# Template register map
Vendor: VendorName Co.Ltd; Series: SeriesName; File version: 1.2
CPU: CM7 r0p1, little endian, MPU, FPU, 4 interrupt priority bits
Registers are 32-bit, read-write, no defined reset value unless marked. A register's access mark holds for its fields unless they carry their own. Offsets are from the block's base; [hi:lo] are bit positions; {n}, {i} and the like mark numbered series.

## MMATH — Math Operation Accelerator
Base 0x400BE000
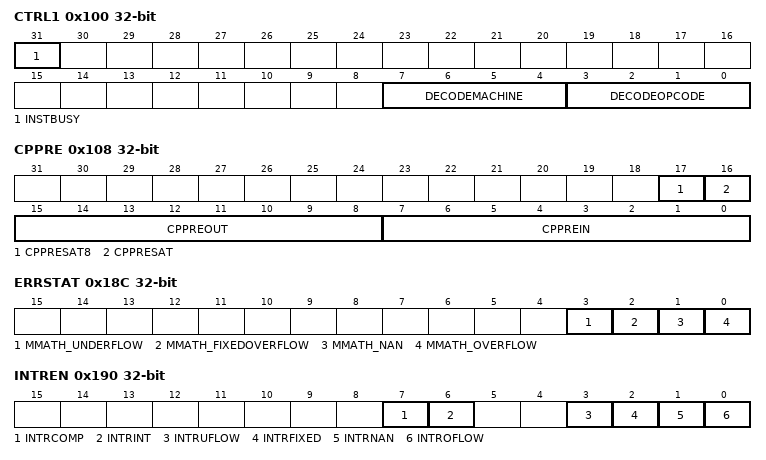
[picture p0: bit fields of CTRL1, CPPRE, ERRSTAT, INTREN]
0x100 CTRL1 — MMATH control register1
  [31] INSTBUSY ro — MMATH INSTBUSY bit: processing when instruct busy
  [7:4] DECODEMACHINE — MMATH DECODEMACHINE[3:0] bit: select corrsponding computational code
  [3:0] DECODEOPCODE — MMATH DECODEOPCODE[3:0] bit: specific opcode for decoder
0x108 CPPRE — MMATH pre-allocated register
  [17] CPPRESAT8 — MMATH CPPRESAT8 bit: co-processor saturation with 8 bits
  [16] CPPRESAT — MMATH CPPRESAT bit: co-processor saturation
  [15:8] CPPREOUT — MMATH CPPREOUT[7:0] bit: co-processor fixed point output
  [7:0] CPPREIN — MMATH CPPREIN[7:0] bit: co-processor scaling of input
0x110 CURSORY — MMATH cursory mode register
  [0] CURSORY — MMATH CURSORY bit: cursory mode enable selection
0x180 CORDICX — MMATH CORDIC input x register
  [31:0] CORDICX — MMATH CORDICX[31:0] bit: CORDIC input x
0x184 CORDICY — MMATH CORDIC input y register
  [31:0] CORDICY — MMATH CORDICY[31:0] bit: CORDIC input y
0x188 CORDICZ — MMATH CORDIC input z register
  [31:0] CORDICZ — MMATH CORDICZ[31:0] bit: CORDIC input z
0x18C ERRSTAT — MMATH error status register
  [3] MMATH_UNDERFLOW — MMATH MMATH_UNDERFLOW bit: underflow flag
  [2] MMATH_FIXEDOVERFLOW — MMATH MMATH_FIXEDOVERFLOW bit: fixed-point number overflow flag
  [1] MMATH_NAN — MMATH MMATH_NAN bit: NAN flag
  [0] MMATH_OVERFLOW — MMATH MMATH_OVERFLOW bit: overflow flag
0x190 INTREN — MMATH interrupt enable register
  [7] INTRCOMP — MMATH INTRCOMP bit: enable interruption request on instruction completion
  [6] INTRINT — MMATH INTRINT bit: global interruption flag enable
  [3] INTRUFLOW — MMATH INTRUFLOW bit: enable interruption request on underflow generation
  [2] INTRFIXED — MMATH INTRFIXED bit: enable interruption request on fixed-pointer number overflow generation
  [1] INTRNAN — MMATH INTRNAN bit: enable interruption request on NAN error generation
  [0] INTROFLOW — MMATH INTROFLOW bit: enable interruption request on overflow generation
0x198 INTRSTAT — MMATH interrupt status register
  [0] INTRSTAT — MMATH INTRSTAT bit: interrupt status register
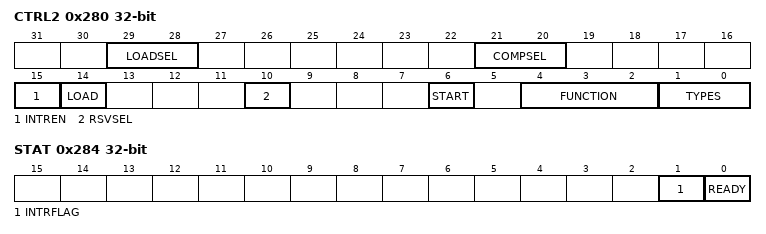
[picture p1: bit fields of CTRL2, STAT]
0x280 CTRL2 — MMATH control register2
  [29:28] LOADSEL — MMATH LOADSEL[1:0] bit: output type and calc unit select
  [21:20] COMPSEL — MMATH COMPSEL[1:0] bit: input type and clac unit select
  [15] INTREN — MMATH INTREN bit: calc finish interrupt enable
  [14] LOAD — MMATH LOAD bit: write 1 load result to read register
  [10] RSVSEL — MMATH RSVSEL bit: result select
  [6] START — MMATH START bit: start calc
  [4:2] FUNCTION — MMATH FUNCTION[2:0] bit: function select from calc types
  [1:0] TYPES — MMATH TYPES[1:0] bit: calc types
0x284 STAT — MMATH status register
  [1] INTRFLAG — MMATH INTRFLAG bit: operation completed interruption status flag bit
  [0] READY ro — MMATH READY bit: READY signal
0x290 WDATA0 — MMATH write data register 0
  [31:0] WDATA — MMATH WDATA[31:0] bit: low 32-bit data written
0x294 WDATA1 — MMATH write data register 1
  [31:0] WDATA — MMATH WDATA[31:0] bit: high 32-bit data written
0x298 RDATA0 ro — MMATH read data register 0
  [31:0] RDATA — MMATH RDATA[31:0] bit: low 32-bit data read
0x29C RDATA1 ro — MMATH read data register 1
  [31:0] RDATA — MMATH RDATA[31:0] bit: high 32-bit data read

## MU — Messaging Unit
Base 0x400C0000
{0x0+4i} TR{i} (i=0..3) — MU transmit register {i}
  [31:0] DATA — MU DATA[31:0] bit: use MUA transmit register {i} to transmit data to MUB
{0x10+4i} RR{i} ro (i=0..3) — MU receive register {i}
  [31:0] DATA — MU DATA[31:0] bit: use MUA receive register {i} to receive data from MUB
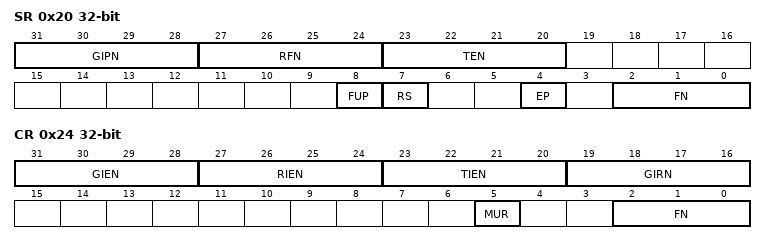
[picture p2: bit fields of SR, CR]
0x20 SR — MU status register
  [31:28] GIPN — MU GIPN[3:0] bit: MUA general interrupt request n pending
  [27:24] RFN ro — MU RFN[3:0] bit: MUA receive register n full
  [23:20] TEN ro — MU TEN[3:0] bit: MUA transmit register n empty
  [8] FUP ro — MU FUP bit: MUA flags update pending
  [7] RS ro — MU RS bit: MUB reset state
  [4] EP ro — MU EP bit: MUA side event pending
  [2:0] FN ro — MU FN[2:0] bit: MUA side flag n
0x24 CR — MU control register
  [31:28] GIEN — MU GIEN[3:0] bit: MUA general purpose interrupt enable n
  [27:24] RIEN — MU RIEN[3:0] bit: MUA receive interrupt enable n
  [23:20] TIEN — MU TIEN[3:0] bit: MUA transmit interrupt enable n
  [19:16] GIRN — MU GIRN[3:0] bit: MUA general purpose interrupt request n
  [5] MUR — MU MUR bit: desc MUR
  [2:0] FN — MU FN[2:0] bit: MUA to MUB flag n
